# M471M_R1_S register map
File version: 1.0
Registers are 32-bit, read-write, reset 0x0 unless marked. A register's access mark holds for its fields unless they carry their own. Offsets are from the block's base; [hi:lo] are bit positions; {n}, {i} and the like mark numbered series; 'fields as' and 'values as' point back to an identical list.

## EADC — EADC Register Map
Base 0x40043000
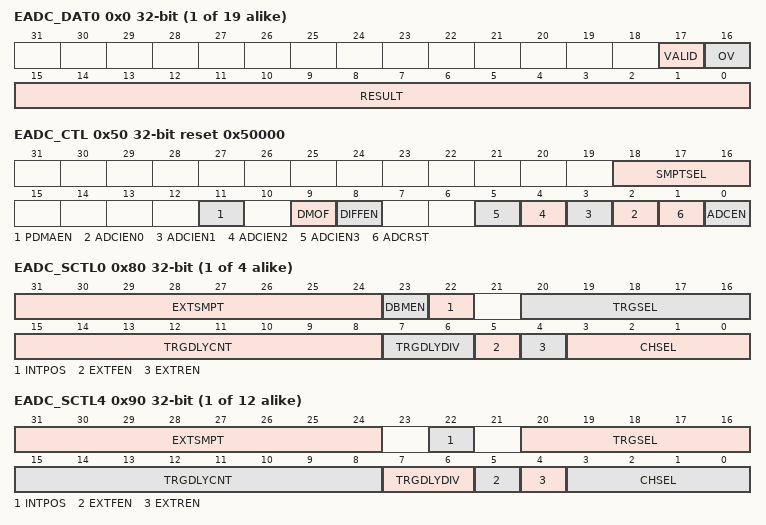
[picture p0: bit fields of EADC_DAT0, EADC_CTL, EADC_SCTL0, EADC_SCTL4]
{0x0+4i} EADC_DAT{i} ro (i=0..18) — A/D Data Register {i} for Sample Module {i}
  [17] VALID — Valid Flag. This bit is set to 1 when corresponding sample module channel analog input conversion is completed and cleared by hardware after EADC_DAT register is read.
    0=Data in RESULT[11:0] bits is not valid; 1=Data in RESULT[11:0] bits is valid
  [16] OV — Overrun Flag. If converted data in RESULT[11:0] has not been read before new conversion result is loaded to this register, OV is set to 1. Note: It is cleared by hardware after EADC_DAT register is read.
    0=Data in RESULT[11:0] is recent conversion result; 1=Data in RESULT[11:0] is overwrite
  [15:0] RESULT — A/D Conversion Result. This field contains 12 bits conversion result. When DMOF (EADC_CTL[9]) is set to 0, 12-bit ADC conversion result with unsigned format will be filled in RESULT[11:0] and zero will be filled in RESULT[15:12]. When DMOF (EADC_CTL[9]) set to 1, 12-bit ADC conversion result with 2'complement format will be filled in RESULT[11:0] and signed bits to will be filled in RESULT[15:12].
0x4C EADC_CURDAT ro — EADC PDMA Current Transfer Data Register
  [17:0] CURDAT — ADC PDMA Current Transfer Data Register. This is a read only register. NOTE: After PDMA read this register, the VAILD of the shadow EADC_DAT register will be automatically cleared.
0x50 EADC_CTL reset 0x50000 — A/D Control Register
  [18:16] SMPTSEL — ADC Internal Sampling Time Selection
    {v}={v+1} ADC clock sampling time (v=0..7)
  [11] PDMAEN — PDMA Transfer Enable Bit. When A/D conversion is completed, the converted data is loaded into EADC_DATn (n: 0 ~ 18) register, user can enable this bit to generate a PDMA data transfer request.
    0=PDMA data transfer Disabled; 1=PDMA data transfer Enabled
  [9] DMOF — ADC Differential Input Mode Output Format. Note: This bit must be set to 0 in single-end analog input mode.
    0=A/D conversion result will be filled in RESULT (EADC_DATn[15:0], n= 0 ~18) with unsigned format; 1=A/D conversion result will be filled in RESULT (EADC_DATn[15:0], n= 0 ~18) with 2'complement format
  [8] DIFFEN — Differential Analog Input Mode Enable Bit
    0=Single-end analog input mode; 1=Differential analog input mode
  [n+2] ADCIEN{n} (n=0..3) — Specific Sample Module A/D ADINT{n} Interrupt Enable Bit. The A/D converter generates a conversion end ADIF{n} (EADC_STATUS2[{n}]) upon the end of specific sample module A/D conversion. If ADCIEN{n} bit is set then conversion end interrupt request ADINT{n} is generated.
    0=Specific sample module A/D ADINT{n} interrupt function Disabled; 1=Specific sample module A/D ADINT{n} interrupt function Enabled
  [1] ADCRST — ADC A/D Converter Control Circuits Reset. Note: ADCRST bit remains 1 during ADC reset, when ADC reset end, the ADCRST bit is automatically cleared to 0.
    0=No effect; 1=Cause ADC control circuits reset to initial state, but not change the ADC registers value
  [0] ADCEN — A/D Converter Enable Bit. Note: Before starting A/D conversion function, this bit should be set to 1. Clear it to 0 to disable A/D converter analog circuit power consumption.
    0=ADC Disabled; 1=ADC Enabled
0x54 EADC_SWTRG wo — A/D Sample Module Software Start Register
  [18:0] SWTRG — A/D Sample Module 0~18 Software Force to Start ADC Conversion. Note: After write this register to start ADC conversion, the EADC_PENDSTS register will show which sample module will conversion. If user want to disable the conversion of the sample module, user can write EADC_PENDSTS register to clear it.
    0=No effect; 1=Cause an ADC conversion when the priority is given to sample module
0x58 EADC_PENDSTS — A/D Start of Conversion Pending Flag Register
  [18:0] STPF — A/D Sample Module 0~18 Start of Conversion Pending Flag. Read:
    0=There is no pending conversion for sample module; 1=Sample module ADC start of conversion is pending. Clear pending flag and stop conversion for corresponding sample module
0x5C EADC_OVSTS — A/D Sample Module Start of Conversion Overrun Flag Register
  [18:0] SPOVF — A/D SAMPLE0~18 Overrun Flag. Note: This bit is cleared by writing 1 to it.
    0=No sample module event overrun; 1=Indicates a new sample module event is generated while an old one event is pending
{0x80+4i} EADC_SCTL{i} (i=0..3) — A/D Sample Module {i} Control Register
  [31:24] EXTSMPT — ADC Sampling Time Extend. When A/D converting at high conversion rate, the sampling time of analog input voltage may not enough if input channel loading is heavy, user can extend A/D sampling time after trigger source is coming to get enough sampling time. The range of start delay time is from 0~255 ADC clock.
  [23] DBMEN — Double Buffer Mode Enable Bit
    0=Sample has one sample result register. (default); 1=Sample has two sample result registers
  [22] INTPOS — Interrupt Flag Position Select
    0=Set ADIFn (EADC_STATUS2[n], n=0~3) at A/D end of conversion; 1=Set ADIFn (EADC_STATUS2[n], n=0~3) at A/D start of conversion
  [20:16] TRGSEL — A/D Sample Module Start of Conversion Trigger Source Selection
  [15:8] TRGDLYCNT — A/D Sample Module Start of Conversion Trigger Delay Time
  [7:6] TRGDLYDIV — A/D Sample Module Start of Conversion Trigger Delay Clock Divider Selection. Trigger delay clock frequency:
    0=ADC_CLK/1; 1=ADC_CLK/2; 2=ADC_CLK/4; 3=ADC_CLK/16
  [5] EXTFEN — A/D External Trigger Falling Edge Enable Bit
    0=Falling edge Disabled when A/D selects STADC as trigger source; 1=Falling edge Enabled when A/D selects STADC as trigger source
  [4] EXTREN — A/D External Trigger Rising Edge Enable Bit
    0=Rising edge Disabled when A/D selects STADC as trigger source; 1=Rising edge Enabled when A/D selects STADC as trigger source
  [3:0] CHSEL — A/D Sample Module Channel Selection
{0x80+4i} EADC_SCTL{i} (i=4..15) — A/D Sample Module {i} Control Register
  [31:24] EXTSMPT — ADC Sampling Time Extend. When A/D converting at high conversion rate, the sampling time of analog input voltage may not enough if input channel loading is heavy, SW can extend A/D sampling time after trigger source is coming to get enough sampling time. The range of start delay time is from 0~255 ADC clock.
  [22] INTPOS — Interrupt Flag Position Select
    values as EADC_SCTL0.INTPOS
  [20:16] TRGSEL — A/D Sample Module Start of Conversion Trigger Source Selection
  [15:8] TRGDLYCNT — A/D Sample Module Start of Conversion Trigger Delay Time
  [7:6] TRGDLYDIV — A/D Sample Module Start of Conversion Trigger Delay Clock Divider Selection. Trigger delay clock frequency:
    0=ADC_CLK/1; 1=ADC_CLK/2; 2=ADC_CLK/4; 3=ADC_CLK/16
  [5] EXTFEN — A/D External Trigger Falling Edge Enable Bit
    values as EADC_SCTL0.EXTFEN
  [4] EXTREN — A/D External Trigger Rising Edge Enable Bit
    values as EADC_SCTL0.EXTREN
  [3:0] CHSEL — A/D Sample Module Channel Selection
{0x80+4i} EADC_SCTL{i} (i=16..18) — A/D Sample Module {i} Control Register
  [31:24] EXTSMPT — ADC Sampling Time Extend. When A/D converting at high conversion rate, the sampling time of analog input voltage may not enough if input channel loading is heavy, SW can extend A/D sampling time after trigger source is coming to get enough sampling time. The range of start delay time is from 0~255 ADC clock.
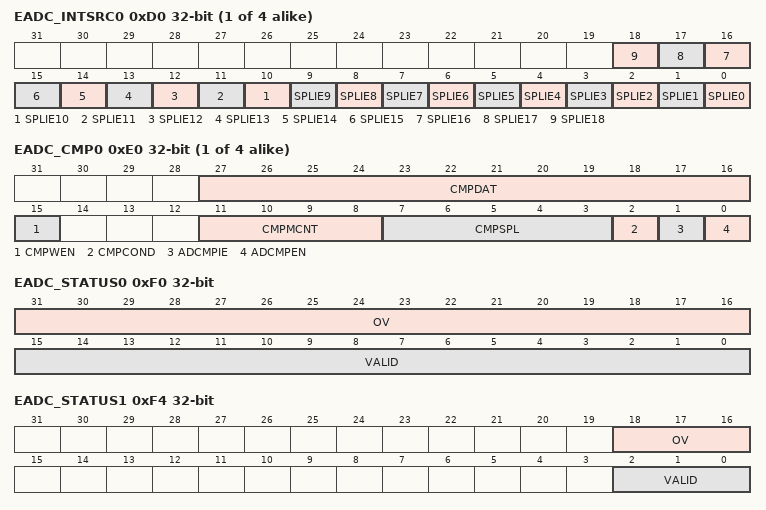
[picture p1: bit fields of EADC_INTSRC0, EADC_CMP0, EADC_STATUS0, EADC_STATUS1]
{0xD0+4i} EADC_INTSRC{i} (i=0..3) — ADC Interrupt {i} Source Enable Control Register.
  [n] SPLIE{n} (n=0..18) — Sample Module {n} Interrupt Enable Bit
    0=Sample Module {n} interrupt Disabled; 1=Sample Module {n} interrupt Enabled
{0xE0+4i} EADC_CMP{i} (i=0..3) — A/D Result Compare Register {i}
  [27:16] CMPDAT — Comparison Data. The 12 bits data is used to compare with conversion result of specified sample module. User can use it to monitor the external analog input pin voltage transition without imposing a load on software.
  [15] CMPWEN — Compare Window Mode Enable Bit. Note: This bit is only present in EADC_CMP0 and EADC_CMP2 register.
    0=ADCMPF0 (EADC_STATUS2[4]) will be set when EADC_CMP0 compared condition matched. ADCMPF2 (EADC_STATUS2[6]) will be set when EADC_CMP2 compared condition matched; 1=ADCMPF0 (EADC_STATUS2[4]) will be set when both EADC_CMP0 and EADC_CMP1 compared condition matched. ADCMPF2 (EADC_STATUS2[6]) will be set when both EADC_CMP2 and EADC_CMP3 compared condition matched
  [11:8] CMPMCNT — Compare Match Count
  [7:3] CMPSPL — Compare Sample Module Selection
    {v}=Sample Module {v} conversion result EADC_DAT{v} is selected to be compared (v=0..18)
  [2] CMPCOND — Compare Condition
    0=Set the compare condition as that when a 12-bit A/D conversion result is less than the 12-bit CMPDAT (EADC_CMPn [27:16]), the internal match counter will increase one; 1=Set the compare condition as that when a 12-bit A/D conversion result is greater or equal to the 12-bit CMPDAT (EADC_CMPn [27:16]), the internal match counter will increase one
  [1] ADCMPIE — A/D Result Compare Interrupt Enable Bit
    0=Compare function interrupt Disabled; 1=Compare function interrupt Enabled
  [0] ADCMPEN — A/D Result Compare Enable Bit
    0=Compare Disabled; 1=Compare Enabled
0xF0 EADC_STATUS0 ro — A/D Status Register 0
  [31:16] OV — EADC_DAT0~15 Overrun Flag
  [15:0] VALID — EADC_DAT0~15 Data Valid Flag
0xF4 EADC_STATUS1 ro — A/D Status Register 1
  [18:16] OV — EADC_DAT16~18 Overrun Flag
  [2:0] VALID — EADC_DAT16~18 Data Valid Flag
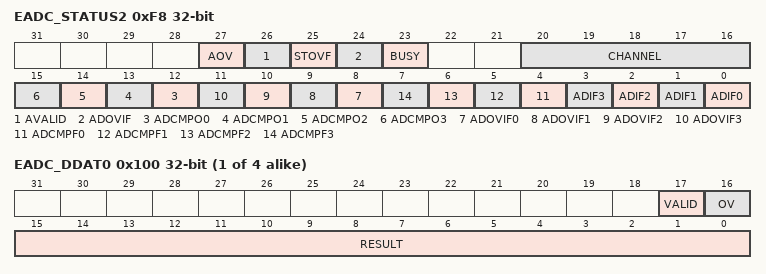
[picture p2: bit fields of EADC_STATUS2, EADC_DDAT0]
0xF8 EADC_STATUS2 — A/D Status Register 2
  [27] AOV — for All Sample Module A/D Result Data Register Overrun Flags Check. Note: This bit will keep 1 when any OVn Flag is equal to 1.
    0=None of sample module data register overrun flag OVn (EADC_DATn[16]) is set to 1; 1=Any one of sample module data register overrun flag OVn (EADC_DATn[16]) is set to 1
  [26] AVALID — for All Sample Module A/D Result Data Register EADC_DAT Data Valid Flag Check. Note: This bit will keep 1 when any VALIDn Flag is equal to 1.
    0=None of sample module data register valid flag VALIDn (EADC_DATn[17]) is set to 1; 1=Any one of sample module data register valid flag VALIDn (EADC_DATn[17]) is set to 1
  [25] STOVF — for All A/D Sample Module Start of Conversion Overrun Flags Check. Note: This bit will keep 1 when any SPOVFn Flag is equal to 1.
    0=None of sample module event overrun flag SPOVFn (EADC_OVSTS[n]) is set to 1; 1=Any one of sample module event overrun flag SPOVFn (EADC_OVSTS[n]) is set to 1
  [24] ADOVIF — All A/D Interrupt Flag Overrun Bits Check. Note: This bit will keep 1 when any ADOVIFn Flag is equal to 1.
    0=None of ADINT interrupt flag ADOVIFn (EADC_STATUS2[11:8]) is overwritten to 1; 1=Any one of ADINT interrupt flag ADOVIFn (EADC_STATUS2[11:8]) is overwritten to 1
  [23] BUSY — Busy/Idle. Note: This bit is read only.
    0=EADC is in idle state; 1=EADC is busy at conversion
  [20:16] CHANNEL — Current Conversion Channel
  [n+12] ADCMPO{n} (n=0..3) — ADC Compare {n} Output Status. The 12 bits compare{n} data CMPDAT{n} (EADC_CMP{n}[27:16]) is used to compare with conversion result of specified sample module. User can use it to monitor the external analog input pin voltage status.
    0=Conversion result in EADC_DAT less than CMPDAT{n} setting; 1=Conversion result in EADC_DAT great than or equal CMPDAT{n} setting
  [n+8] ADOVIF{n} (n=0..3) — A/D ADINT{n} Interrupt Flag Overrun. Note: This bit is cleared by writing 1 to it.
    0=ADINT{n} interrupt flag is not overwritten to 1; 1=ADINT{n} interrupt flag is overwritten to 1
  [n+4] ADCMPF{n} (n=0..3) — ADC Compare {n} Flag. When the specific sample module A/D conversion result meets setting condition in EADC_CMP{n} then this bit is set to 1. Note: This bit is cleared by writing 1 to it.
    0=Conversion result in EADC_DAT does not meet EADC_CMP{n} register setting; 1=Conversion result in EADC_DAT meets EADC_CMP{n} register setting
  [n] ADIF{n} (n=0..3) — A/D ADINT{n} Interrupt Flag. Note1: This bit is cleared by writing 1 to it. Note2:This bit indicates whether an A/D conversion of specific sample module has been completed
    0=No ADINT{n} interrupt pulse received; 1=ADINT{n} interrupt pulse has been received
0xFC EADC_STATUS3 ro reset 0x1F — A/D Status Register 3
  [4:0] CURSPL — ADC Current Sample Module. This register show the current ADC is controlled by which sample module control logic modules. If the ADC is Idle, this bit filed will set to 0x1F. This is a read only register.
{0x100+4i} EADC_DDAT{i} ro (i=0..3) — A/D Double Data Register {i} for Sample Module {i}
  [17] VALID — Valid Flag
    0=Double data in RESULT (EADC_DDATn[15:0]) is not valid; 1=Double data in RESULT (EADC_DDATn[15:0]) is valid
  [16] OV — Overrun Flag. If converted data in RESULT[15:0] has not been read before new conversion result is loaded to this register, OV is set to 1. It is cleared by hardware after EADC_DDAT register is read.
    0=Data in RESULT (EADC_DATn[15:0], n=0~3) is recent conversion result; 1=Data in RESULT (EADC_DATn[15:0], n=0~3) is overwrite
  [15:0] RESULT — A/D Conversion Results. This field contains 12 bits conversion results. When the DMOF (EADC_CTL[9]) is set to 0, 12-bit ADC conversion result with unsigned format will be filled in RESULT [11:0] and zero will be filled in RESULT [15:12]. When DMOF (EADC_CTL[9]) set to 1, 12-bit ADC conversion result with 2'complement format will be filled in RESULT [11:0] and signed bits to will be filled in RESULT [15:12].
